VERSION ""

NS_ :

BS_:

BU_: INTERCEPTOR EBCM NEO ADAS PCM EPS VSA SCM BDY XXX EPB Vector__XXX EON S

BO_ 57 XXX_1: 3 XXX
 SG_ COUNTER : 21|2@0+ (1,0) [0|15] "" NEO
 SG_ CHECKSUM : 19|4@0+ (1,0) [0|3] "" NEO

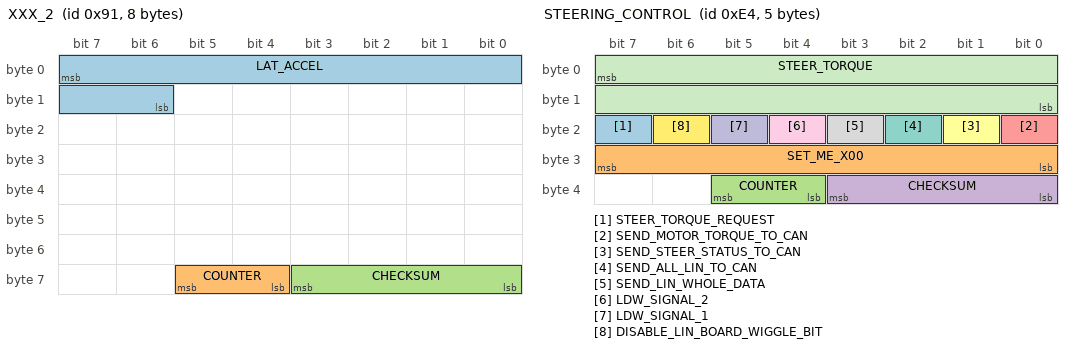
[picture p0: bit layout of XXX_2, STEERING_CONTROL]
BO_ 145 XXX_2: 8 XXX
 SG_ LAT_ACCEL : 7|10@0+ (0.02,-512) [-20|20] "m/s2" NEO
 SG_ COUNTER : 61|2@0+ (1,0) [0|3] "" NEO
 SG_ CHECKSUM : 59|4@0+ (1,0) [0|15] "" NEO

BO_ 228 STEERING_CONTROL: 5 ADAS
 SG_ STEER_TORQUE_REQUEST : 23|1@0+ (1,0) [0|1] "" EPS
 SG_ SET_ME_X00 : 31|8@0+ (1,0) [0|0] "" EPS
 SG_ COUNTER : 37|2@0+ (1,0) [0|3] "" EPS
 SG_ CHECKSUM : 35|4@0+ (1,0) [0|3] "" EPS
 SG_ SEND_MOTOR_TORQUE_TO_CAN : 16|1@0+ (1,0) [0|1] "" XXX
 SG_ SEND_STEER_STATUS_TO_CAN : 17|1@0+ (1,0) [0|1] "" XXX
 SG_ SEND_ALL_LIN_TO_CAN : 18|1@0+ (1,0) [0|1] "" XXX
 SG_ SEND_LIN_WHOLE_DATA : 19|1@0+ (1,0) [0|1] "" XXX
 SG_ LDW_SIGNAL_2 : 20|1@0+ (1,0) [0|1] "" XXX
 SG_ LDW_SIGNAL_1 : 21|1@0+ (1,0) [0|1] "" XXX
 SG_ STEER_TORQUE : 7|16@0- (1,0) [-3840|3840] "" EPS
 SG_ DISABLE_LIN_BOARD_WIGGLE_BIT : 22|1@0+ (1,0) [0|1] "" XXX

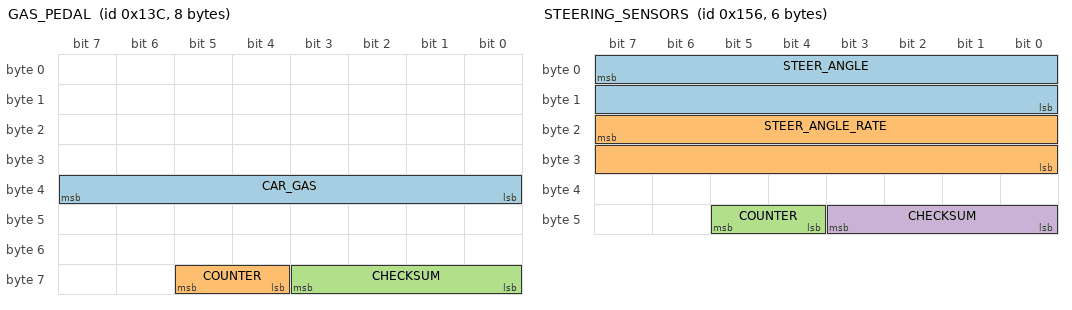
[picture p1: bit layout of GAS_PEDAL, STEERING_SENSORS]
BO_ 316 GAS_PEDAL: 8 PCM
 SG_ CAR_GAS : 39|8@0+ (1,0) [0|255] "" NEO
 SG_ COUNTER : 61|2@0+ (1,0) [0|3] "" NEO
 SG_ CHECKSUM : 59|4@0+ (1,0) [0|15] "" NEO

BO_ 342 STEERING_SENSORS: 6 EPS
 SG_ STEER_ANGLE : 7|16@0- (-0.1,0) [-500|500] "deg" NEO
 SG_ STEER_ANGLE_RATE : 23|16@0- (1,0) [-3000|3000] "deg/s" NEO
 SG_ COUNTER : 45|2@0+ (1,0) [0|3] "" NEO
 SG_ CHECKSUM : 43|4@0+ (1,0) [0|15] "" NEO

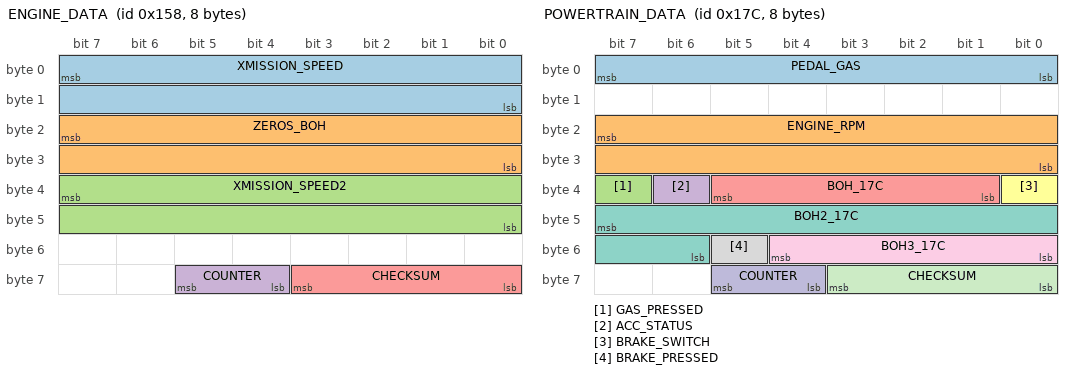
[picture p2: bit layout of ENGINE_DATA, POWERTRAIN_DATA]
BO_ 344 ENGINE_DATA: 8 PCM
 SG_ XMISSION_SPEED : 7|16@0+ (0.002759506,0) [0|70] "m/s" NEO
 SG_ ZEROS_BOH : 23|16@0+ (1,0) [0|15000] "" NEO
 SG_ XMISSION_SPEED2 : 39|16@0+ (0.002759506,0) [0|70] "m/s" NEO
 SG_ COUNTER : 61|2@0+ (1,0) [0|3] "" NEO
 SG_ CHECKSUM : 59|4@0+ (1,0) [0|15] "" NEO

BO_ 380 POWERTRAIN_DATA: 8 PCM
 SG_ PEDAL_GAS : 7|8@0+ (1,0) [0|255] "" NEO
 SG_ ENGINE_RPM : 23|16@0+ (1,0) [0|15000] "rpm" NEO
 SG_ GAS_PRESSED : 39|1@0+ (1,0) [0|1] "" NEO
 SG_ ACC_STATUS : 38|1@0+ (1,0) [0|1] "rpm" EON
 SG_ BOH_17C : 37|5@0+ (1,0) [0|1] "rpm" NEO
 SG_ BRAKE_SWITCH : 32|1@0+ (1,0) [0|1] "rpm" NEO
 SG_ BOH2_17C : 47|10@0+ (1,0) [0|1] "rpm" NEO
 SG_ BRAKE_PRESSED : 53|1@0+ (1,0) [0|1] "" NEO
 SG_ BOH3_17C : 52|5@0+ (1,0) [0|1] "rpm" NEO
 SG_ COUNTER : 61|2@0+ (1,0) [0|3] "" NEO
 SG_ CHECKSUM : 59|4@0+ (1,0) [0|3] "" NEO

BO_ 398 XXX_3: 3 XXX
 SG_ COUNTER : 21|2@0+ (1,0) [0|15] "" XXX
 SG_ CHECKSUM : 19|4@0+ (1,0) [0|3] "" XXX

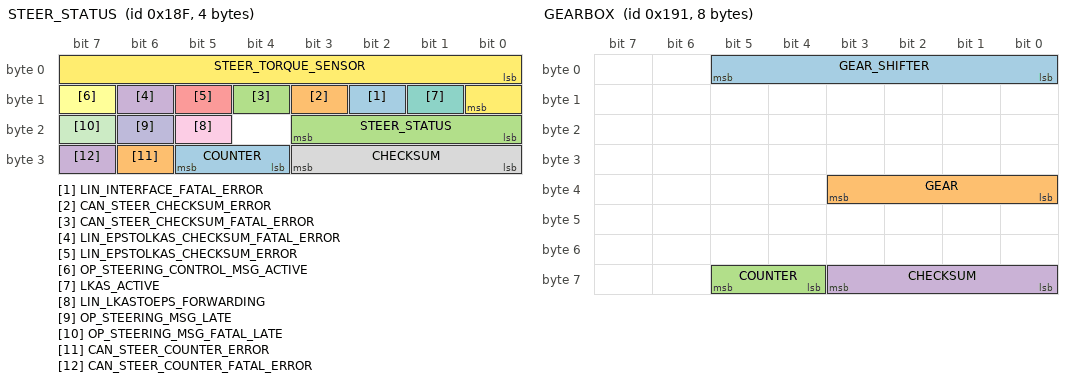
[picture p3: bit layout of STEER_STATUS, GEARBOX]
BO_ 399 STEER_STATUS: 4 EPS
 SG_ LIN_INTERFACE_FATAL_ERROR : 10|1@0+ (1,0) [0|1] "" XXX
 SG_ CAN_STEER_CHECKSUM_ERROR : 11|1@0+ (1,0) [0|1] "" XXX
 SG_ CAN_STEER_CHECKSUM_FATAL_ERROR : 12|1@0+ (1,0) [0|1] "" XXX
 SG_ LIN_EPSTOLKAS_CHECKSUM_FATAL_ERROR : 14|1@0+ (1,0) [0|1] "" XXX
 SG_ LIN_EPSTOLKAS_CHECKSUM_ERROR : 13|1@0+ (1,0) [0|1] "" XXX
 SG_ OP_STEERING_CONTROL_MSG_ACTIVE : 15|1@0+ (1,0) [0|1] "" XXX
 SG_ LKAS_ACTIVE : 9|1@0+ (1,0) [0|1] "" XXX
 SG_ CHECKSUM : 27|4@0+ (1,0) [0|3] "" EON
 SG_ LIN_LKASTOEPS_FORWARDING : 21|1@0+ (1,0) [0|1] "" XXX
 SG_ OP_STEERING_MSG_LATE : 22|1@0+ (1,0) [0|1] "" XXX
 SG_ OP_STEERING_MSG_FATAL_LATE : 23|1@0+ (1,0) [0|1] "" XXX
 SG_ STEER_TORQUE_SENSOR : 0|9@1- (1,0) [-256|256] "" XXX
 SG_ COUNTER : 29|2@0+ (1,0) [0|3] "" EON
 SG_ CAN_STEER_COUNTER_ERROR : 30|1@0+ (1,0) [0|1] "" XXX
 SG_ STEER_STATUS : 16|4@1+ (1,0) [0|15] "" XXX
 SG_ CAN_STEER_COUNTER_FATAL_ERROR : 31|1@0+ (1,0) [0|1] "" XXX

BO_ 401 GEARBOX: 8 PCM
 SG_ GEAR_SHIFTER : 5|6@0+ (1,0) [0|63] "" NEO
 SG_ GEAR : 35|4@0+ (1,0) [0|15] "" NEO
 SG_ COUNTER : 61|2@0+ (1,0) [0|3] "" NEO
 SG_ CHECKSUM : 59|4@0+ (1,0) [0|15] "" NEO

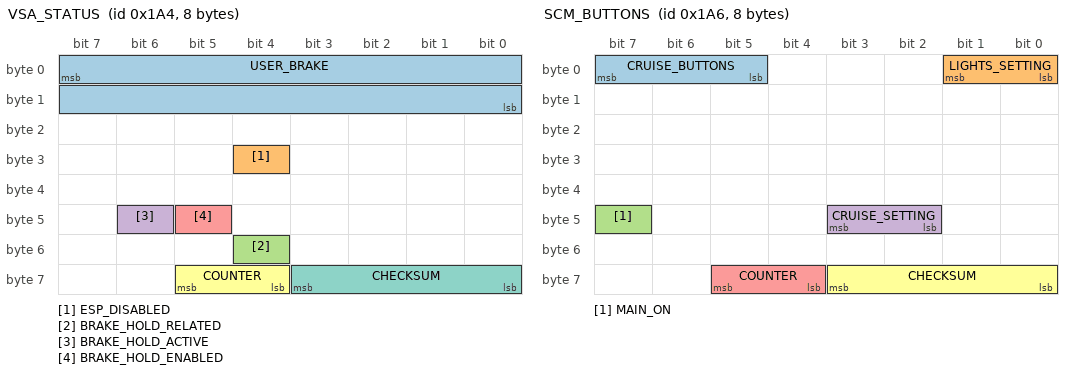
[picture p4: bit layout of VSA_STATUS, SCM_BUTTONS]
BO_ 420 VSA_STATUS: 8 VSA
 SG_ USER_BRAKE : 7|16@0+ (0.015625,-1.609375) [0|1000] "" EON
 SG_ ESP_DISABLED : 28|1@0+ (1,0) [0|1] "" EON
 SG_ BRAKE_HOLD_RELATED : 52|1@0+ (1,0) [0|1] "" XXX
 SG_ BRAKE_HOLD_ACTIVE : 46|1@0+ (1,0) [0|1] "" EON
 SG_ BRAKE_HOLD_ENABLED : 45|1@0+ (1,0) [0|1] "" EON
 SG_ COUNTER : 61|2@0+ (1,0) [0|3] "" EON
 SG_ CHECKSUM : 59|4@0+ (1,0) [0|15] "" EON

BO_ 422 SCM_BUTTONS: 8 SCM
 SG_ CRUISE_BUTTONS : 7|3@0+ (1,0) [0|7] "" NEO
 SG_ LIGHTS_SETTING : 1|2@0+ (1,0) [0|3] "" NEO
 SG_ MAIN_ON : 47|1@0+ (1,0) [0|1] "" NEO
 SG_ CRUISE_SETTING : 43|2@0+ (1,0) [0|3] "" NEO
 SG_ COUNTER : 61|2@0+ (1,0) [0|3] "" NEO
 SG_ CHECKSUM : 59|4@0+ (1,0) [0|15] "" NEO

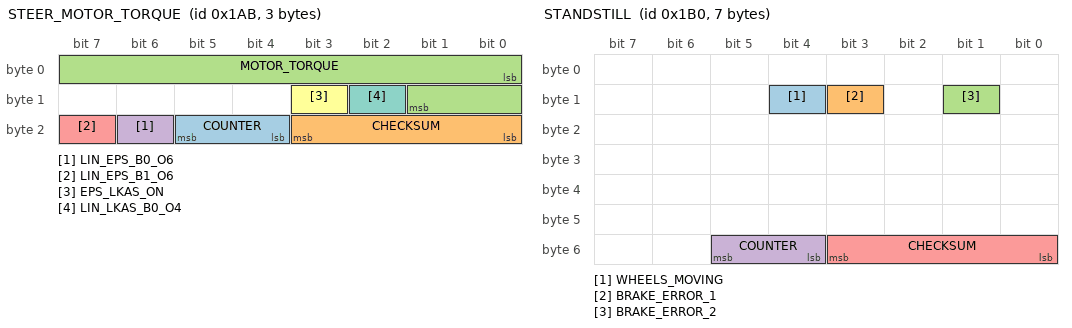
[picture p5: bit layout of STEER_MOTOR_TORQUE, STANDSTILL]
BO_ 427 STEER_MOTOR_TORQUE: 3 EPS
 SG_ COUNTER : 21|2@0+ (1,0) [0|3] "" EON
 SG_ CHECKSUM : 19|4@0+ (1,0) [0|15] "" EON
 SG_ MOTOR_TORQUE : 0|10@1- (1,0) [-512|512] "" XXX
 SG_ LIN_EPS_B0_O6 : 22|1@0+ (1,0) [0|1] "" XXX
 SG_ LIN_EPS_B1_O6 : 23|1@0+ (1,0) [0|1] "" XXX
 SG_ EPS_LKAS_ON : 11|1@0+ (1,0) [0|1] "" XXX
 SG_ LIN_LKAS_B0_O4 : 10|1@0+ (1,0) [0|1] "" XXX

BO_ 426 XXX_4: 8 VSA
 SG_ COUNTER : 61|2@0+ (1,0) [0|3] "" NEO
 SG_ CHECKSUM : 59|4@0+ (1,0) [0|15] "" NEO

BO_ 432 STANDSTILL: 7 VSA
 SG_ WHEELS_MOVING : 12|1@0+ (1,0) [0|1] "" NEO
 SG_ BRAKE_ERROR_1 : 11|1@0+ (1,0) [0|1] "" NEO
 SG_ BRAKE_ERROR_2 : 9|1@0+ (1,0) [0|1] "" NEO
 SG_ COUNTER : 53|2@0+ (1,0) [0|3] "" NEO
 SG_ CHECKSUM : 51|4@0+ (1,0) [0|15] "" NEO

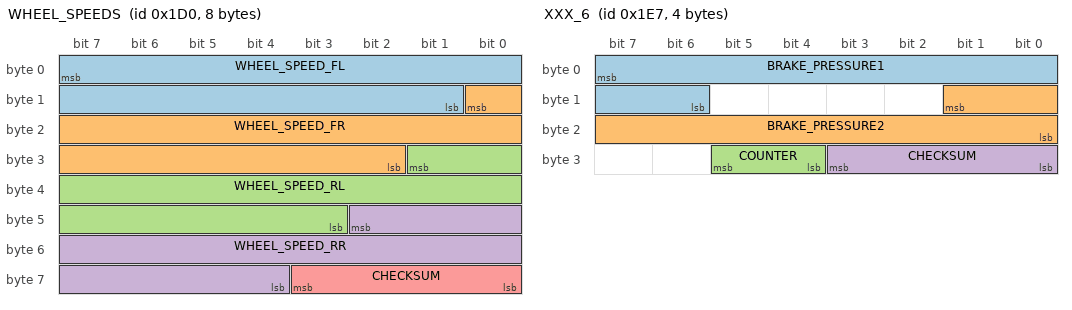
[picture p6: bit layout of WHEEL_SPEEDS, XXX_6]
BO_ 464 WHEEL_SPEEDS: 8 VSA
 SG_ WHEEL_SPEED_FL : 7|15@0+ (0.01,0) [0|250] "kph" EON
 SG_ WHEEL_SPEED_FR : 8|15@0+ (0.01,0) [0|250] "kph" EON
 SG_ WHEEL_SPEED_RL : 25|15@0+ (0.01,0) [0|250] "kph" EON
 SG_ WHEEL_SPEED_RR : 42|15@0+ (0.01,0) [0|250] "kph" EON
 SG_ CHECKSUM : 59|4@0+ (1,0) [0|3] "" EON

BO_ 476 XXX_5: 4 XXX
 SG_ COUNTER : 29|2@0+ (1,0) [0|3] "" XXX
 SG_ CHECKSUM : 27|4@0+ (1,0) [0|15] "" XXX

BO_ 487 XXX_6: 4 VSA
 SG_ BRAKE_PRESSURE1 : 7|10@0+ (0.015625,-103) [0|1000] "" NEO
 SG_ BRAKE_PRESSURE2 : 9|10@0+ (0.015625,-103) [0|1000] "" NEO
 SG_ COUNTER : 29|2@0+ (1,0) [0|3] "" XXX
 SG_ CHECKSUM : 27|4@0+ (1,0) [0|15] "" XXX

BO_ 490 VEHICLE_DYNAMICS: 8 VSA
 SG_ LONG_ACCEL : 23|16@0- (0.0015384,0) [-20|20] "m/s2" NEO
 SG_ COUNTER : 61|2@0+ (1,0) [0|3] "" XXX
 SG_ CHECKSUM : 59|4@0+ (1,0) [0|15] "" XXX

BO_ 506 BRAKE_COMMAND: 8 ADAS
 SG_ COMPUTER_BRAKE : 7|10@0+ (1,0) [0|1] "" EBCM
 SG_ SET_ME_X00 : 13|5@0+ (1,0) [0|1] "" EBCM
 SG_ BRAKE_PUMP_REQUEST : 8|1@0+ (1,0) [0|1] "" EBCM
 SG_ SET_ME_X00_2 : 23|3@0+ (1,0) [0|1] "" EBCM
 SG_ CRUISE_OVERRIDE : 20|1@0+ (1,0) [0|1] "" EBCM
 SG_ SET_ME_X00_3 : 19|1@0+ (1,0) [0|1] "" EBCM
 SG_ CRUISE_FAULT_CMD : 18|1@0+ (1,0) [0|1] "" EBCM
 SG_ CRUISE_CANCEL_CMD : 17|1@0+ (1,0) [0|1] "" EBCM
 SG_ COMPUTER_BRAKE_REQUEST : 16|1@0+ (1,0) [0|1] "" EBCM
 SG_ SET_ME_1 : 31|1@0+ (1,0) [0|1] "" EBCM
 SG_ AEB_REQ_1 : 29|1@0+ (1,0) [0|1] "" XXX
 SG_ AEB_REQ_2 : 26|3@0+ (1,0) [0|7] "" XXX
 SG_ BRAKE_LIGHTS : 39|1@0+ (1,0) [0|1] "" EBCM
 SG_ CRUISE_STATES : 38|7@0+ (1,0) [0|1] "" EBCM
 SG_ CHIME : 47|3@0+ (1,0) [0|7] "" EBCM
 SG_ SET_ME_X00_4 : 44|1@0+ (1,0) [0|1] "" EBCM
 SG_ FCW : 43|2@0+ (1,0) [0|3] "" EBCM
 SG_ AEB_STATUS : 41|2@0+ (1,0) [0|3] "" XXX
 SG_ SET_ME_X00_5 : 55|8@0+ (1,0) [0|0] "" EBCM
 SG_ COUNTER : 61|2@0+ (1,0) [0|3] "" EBCM
 SG_ CHECKSUM : 59|4@0+ (1,0) [0|15] "" EBCM

BO_ 507 XXX_7: 1 XXX

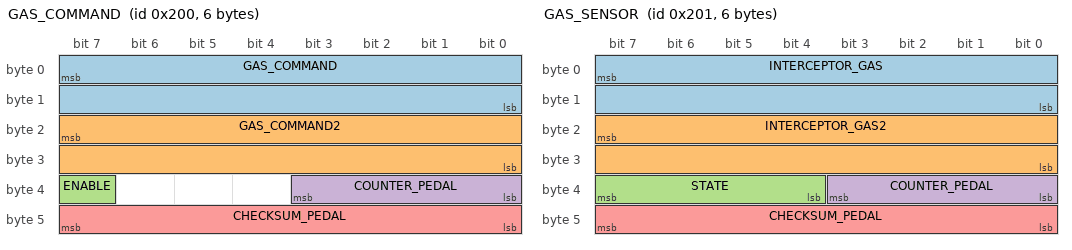
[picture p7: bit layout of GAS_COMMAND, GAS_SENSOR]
BO_ 512 GAS_COMMAND: 6 EON
 SG_ GAS_COMMAND : 7|16@0+ (0.126992032,-83.3) [0|1] "" INTERCEPTOR
 SG_ GAS_COMMAND2 : 23|16@0+ (0.253984064,-83.3) [0|1] "" INTERCEPTOR
 SG_ ENABLE : 39|1@0+ (1,0) [0|1] "" INTERCEPTOR
 SG_ COUNTER_PEDAL : 35|4@0+ (1,0) [0|15] "" INTERCEPTOR
 SG_ CHECKSUM_PEDAL : 47|8@0+ (1,0) [0|255] "" INTERCEPTOR

BO_ 513 GAS_SENSOR: 6 INTERCEPTOR
 SG_ INTERCEPTOR_GAS : 7|16@0+ (0.126992032,-83.3) [0|1] "" EON
 SG_ INTERCEPTOR_GAS2 : 23|16@0+ (0.253984064,-83.3) [0|1] "" EON
 SG_ STATE : 39|4@0+ (1,0) [0|15] "" EON
 SG_ COUNTER_PEDAL : 35|4@0+ (1,0) [0|15] "" EON
 SG_ CHECKSUM_PEDAL : 47|8@0+ (1,0) [0|255] "" EON

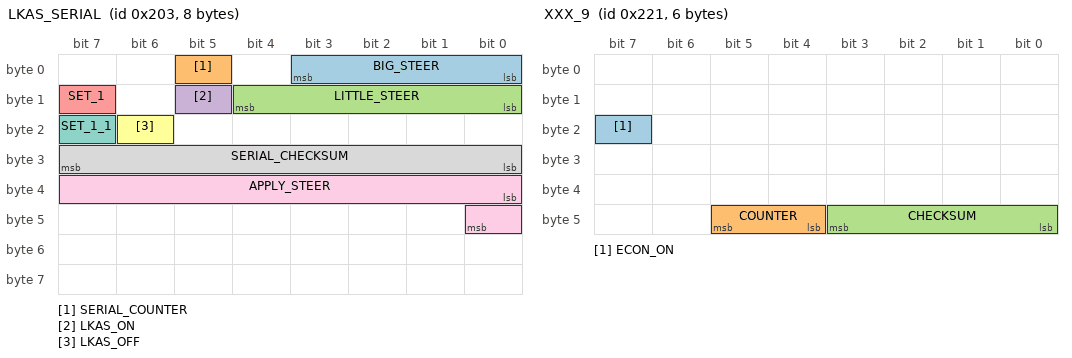
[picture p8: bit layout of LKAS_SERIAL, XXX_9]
BO_ 515 LKAS_SERIAL: 8 XXX
 SG_ BIG_STEER : 3|4@0- (1,0) [0|15] "" XXX
 SG_ SERIAL_COUNTER : 5|1@0+ (1,0) [0|1] "" XXX
 SG_ LITTLE_STEER : 12|5@0- (1,0) [0|31] "" XXX
 SG_ LKAS_ON : 13|1@0+ (1,0) [0|1] "" XXX
 SG_ SET_1 : 15|1@0+ (1,0) [0|1] "" XXX
 SG_ LKAS_OFF : 22|1@0+ (1,0) [0|1] "" XXX
 SG_ SET_1_1 : 23|1@0+ (1,0) [0|1] "" XXX
 SG_ SERIAL_CHECKSUM : 24|8@1+ (1,32) [0|255] "" XXX
 SG_ APPLY_STEER : 32|9@1- (1,0) [-256|255] "" XXX

BO_ 542 XXX_8: 7 XXX
 SG_ COUNTER : 53|2@0+ (1,0) [0|3] "" XXX
 SG_ CHECKSUM : 51|4@0+ (1,0) [0|15] "" XXX

BO_ 545 XXX_9: 6 SCM
 SG_ ECON_ON : 23|1@0+ (1,0) [0|1] "" XXX
 SG_ COUNTER : 45|2@0+ (1,0) [0|3] "" BDY
 SG_ CHECKSUM : 43|4@0+ (1,0) [0|15] "" BDY

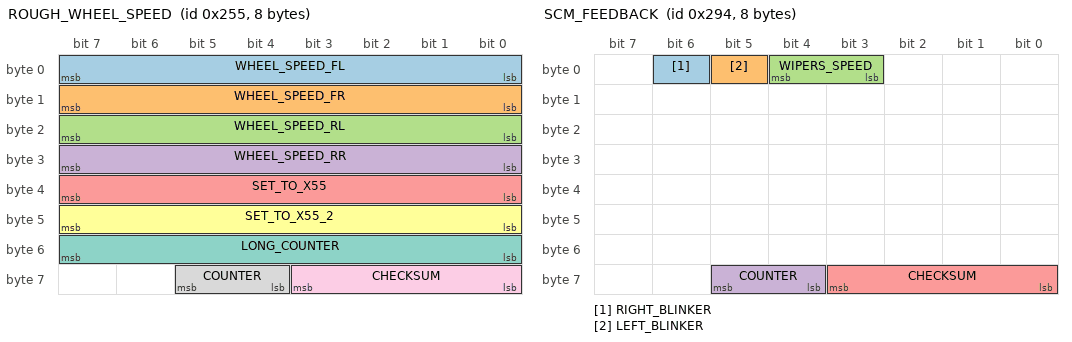
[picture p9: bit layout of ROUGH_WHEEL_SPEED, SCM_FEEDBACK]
BO_ 597 ROUGH_WHEEL_SPEED: 8 VSA
 SG_ WHEEL_SPEED_FL : 7|8@0+ (1,0) [0|255] "mph" NEO
 SG_ WHEEL_SPEED_FR : 15|8@0+ (1,0) [0|255] "mph" NEO
 SG_ WHEEL_SPEED_RL : 23|8@0+ (1,0) [0|255] "mph" NEO
 SG_ WHEEL_SPEED_RR : 31|8@0+ (1,0) [0|255] "mph" NEO
 SG_ SET_TO_X55 : 39|8@0+ (1,0) [0|255] "" XXX
 SG_ SET_TO_X55_2 : 47|8@0+ (1,0) [0|255] "" NEO
 SG_ LONG_COUNTER : 55|8@0+ (1,0) [0|255] "" XXX
 SG_ COUNTER : 61|2@0+ (1,0) [0|3] "" XXX
 SG_ CHECKSUM : 59|4@0+ (1,0) [0|15] "" XXX

BO_ 660 SCM_FEEDBACK: 8 SCM
 SG_ RIGHT_BLINKER : 6|1@0+ (1,0) [0|1] "" NEO
 SG_ LEFT_BLINKER : 5|1@0+ (1,0) [0|1] "" NEO
 SG_ WIPERS_SPEED : 4|2@0+ (1,0) [0|3] "" NEO
 SG_ COUNTER : 61|2@0+ (1,0) [0|3] "" XXX
 SG_ CHECKSUM : 59|4@0+ (1,0) [0|15] "" XXX

BO_ 661 XXX_10: 4 XXX
 SG_ COUNTER : 29|2@0+ (1,0) [0|3] "" XXX
 SG_ CHECKSUM : 27|4@0+ (1,0) [0|15] "" XXX

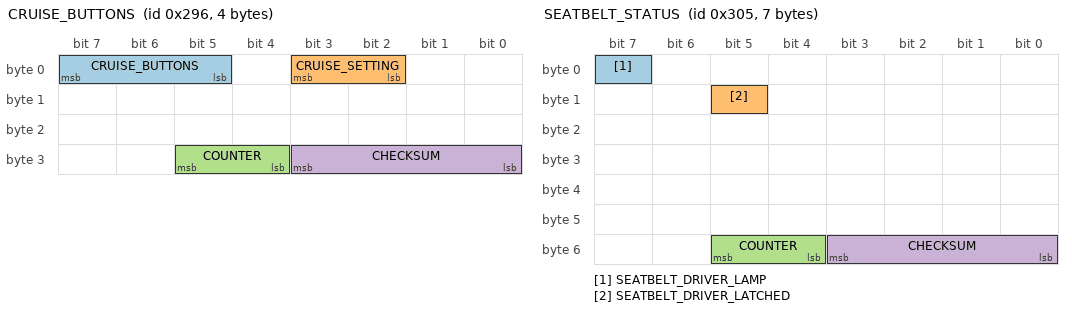
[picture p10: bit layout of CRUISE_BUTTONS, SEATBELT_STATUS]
BO_ 662 CRUISE_BUTTONS: 4 SCM
 SG_ CRUISE_BUTTONS : 7|3@0+ (1,0) [0|7] "" NEO
 SG_ CRUISE_SETTING : 3|2@0+ (1,0) [0|3] "" NEO
 SG_ COUNTER : 29|2@0+ (1,0) [0|3] "" XXX
 SG_ CHECKSUM : 27|4@0+ (1,0) [0|15] "" XXX

BO_ 773 SEATBELT_STATUS: 7 BDY
 SG_ SEATBELT_DRIVER_LAMP : 7|1@0+ (1,0) [0|1] "" NEO
 SG_ SEATBELT_DRIVER_LATCHED : 13|1@0+ (1,0) [0|1] "" NEO
 SG_ COUNTER : 53|2@0+ (1,0) [0|3] "" NEO
 SG_ CHECKSUM : 51|4@0+ (1,0) [0|15] "" NEO

BO_ 777 XXX_11: 8 XXX
 SG_ COUNTER : 61|2@0+ (1,0) [0|3] "" XXX
 SG_ CHECKSUM : 59|4@0+ (1,0) [0|15] "" XXX

BO_ 780 ACC_HUD: 8 ADAS
 SG_ PCM_SPEED : 7|16@0+ (0.01,0) [0|250] "kph" BDY
 SG_ PCM_GAS : 23|7@0+ (1,0) [0|127] "" BDY
 SG_ ZEROS_BOH : 16|1@0+ (1,0) [0|255] "" BDY
 SG_ CRUISE_SPEED : 31|8@0+ (1,0) [0|255] "" BDY
 SG_ DTC_MODE : 39|1@0+ (1,0) [0|1] "" BDY
 SG_ BOH : 38|1@0+ (1,0) [0|1] "" BDY
 SG_ ACC_PROBLEM : 37|1@0+ (1,0) [0|1] "" BDY
 SG_ FCM_OFF : 36|1@0+ (1,0) [0|1] "" BDY
 SG_ FCM_OFF_2 : 35|1@0+ (1,0) [0|1] "" BDY
 SG_ FCM_PROBLEM : 34|1@0+ (1,0) [0|1] "" BDY
 SG_ RADAR_OBSTRUCTED : 33|1@0+ (1,0) [0|1] "" BDY
 SG_ ENABLE_MINI_CAR : 32|1@0+ (1,0) [0|1] "" BDY
 SG_ HUD_DISTANCE : 47|2@0+ (1,0) [0|3] "" BDY
 SG_ HUD_DISTANCE_3 : 52|1@0+ (1,0) [0|1] "" BDY
 SG_ HUD_LEAD : 45|2@0+ (1,0) [0|3] "" BDY
 SG_ BOH_3 : 43|1@0+ (1,0) [0|3] "" BDY
 SG_ BOH_4 : 42|1@0+ (1,0) [0|3] "" BDY
 SG_ BOH_5 : 41|1@0+ (1,0) [0|3] "" BDY
 SG_ CRUISE_CONTROL_LABEL : 40|1@0+ (1,0) [0|3] "" BDY
 SG_ SET_ME_X01_2 : 55|1@0+ (1,0) [0|1] "" BDY
 SG_ CHIME : 51|3@0+ (1,0) [0|1] "" BDY
 SG_ IMPERIAL_UNIT : 54|1@0+ (1,0) [0|1] "" BDY
 SG_ SET_ME_X01 : 48|1@0+ (1,0) [0|1] "" BDY
 SG_ ICONS : 63|2@0+ (1,0) [0|1] "" BDY
 SG_ COUNTER : 61|2@0+ (1,0) [0|3] "" BDY
 SG_ CHECKSUM : 59|4@0+ (1,0) [0|15] "" BDY

BO_ 800 XXX_12: 8 XXX
 SG_ COUNTER : 61|2@0+ (1,0) [0|3] "" XXX
 SG_ CHECKSUM : 59|4@0+ (1,0) [0|15] "" XXX

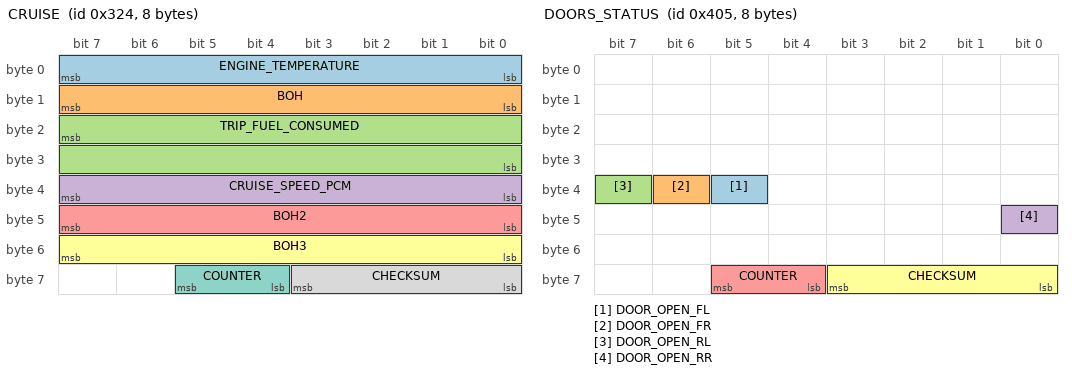
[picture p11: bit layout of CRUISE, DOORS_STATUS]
BO_ 804 CRUISE: 8 PCM
 SG_ ENGINE_TEMPERATURE : 7|8@0+ (1,0) [0|255] "" NEO
 SG_ BOH : 15|8@0+ (1,0) [0|255] "" NEO
 SG_ TRIP_FUEL_CONSUMED : 23|16@0+ (1,0) [0|255] "" NEO
 SG_ CRUISE_SPEED_PCM : 39|8@0+ (1,0) [0|255] "" NEO
 SG_ BOH2 : 47|8@0- (1,0) [0|255] "" NEO
 SG_ BOH3 : 55|8@0+ (1,0) [0|255] "" NEO
 SG_ COUNTER : 61|2@0+ (1,0) [0|3] "" NEO
 SG_ CHECKSUM : 59|4@0+ (1,0) [0|15] "" NEO

BO_ 808 XXX_13: 8 XXX
 SG_ COUNTER : 61|2@0+ (1,0) [0|3] "" XXX
 SG_ CHECKSUM : 59|4@0+ (1,0) [0|15] "" XXX

BO_ 829 LKAS_HUD: 5 ADAS
 SG_ CAM_TEMP_HIGH : 7|1@0+ (1,0) [0|255] "" BDY
 SG_ SET_ME_X41 : 6|7@0+ (1,0) [0|127] "" BDY
 SG_ BOH : 23|2@0+ (1,0) [0|4] "" BDY
 SG_ DASHED_LANES : 14|1@0+ (1,0) [0|1] "" BDY
 SG_ DTC : 13|1@0+ (1,0) [0|1] "" BDY
 SG_ LKAS_PROBLEM : 12|1@0+ (1,0) [0|1] "" BDY
 SG_ LKAS_OFF : 11|1@0+ (1,0) [0|1] "" BDY
 SG_ SOLID_LANES : 10|1@0+ (1,0) [0|1] "" BDY
 SG_ LDW_RIGHT : 9|1@0+ (1,0) [0|1] "" BDY
 SG_ STEERING_REQUIRED : 8|1@0+ (1,0) [0|1] "" BDY
 SG_ LDW_PROBLEM : 21|1@0+ (1,0) [0|1] "" BDY
 SG_ BEEP : 17|2@0+ (1,0) [0|1] "" BDY
 SG_ LDW_ON : 28|1@0+ (1,0) [0|1] "" BDY
 SG_ LDW_OFF : 27|1@0+ (1,0) [0|1] "" BDY
 SG_ CLEAN_WINDSHIELD : 26|1@0+ (1,0) [0|1] "" BDY
 SG_ SET_ME_X48 : 31|8@0+ (1,0) [0|255] "" BDY
 SG_ COUNTER : 37|2@0+ (1,0) [0|3] "" BDY
 SG_ CHECKSUM : 35|4@0+ (1,0) [0|15] "" BDY

BO_ 871 XXX_14: 8 XXX
 SG_ COUNTER : 61|2@0+ (1,0) [0|3] "" XXX
 SG_ CHECKSUM : 59|4@0+ (1,0) [0|15] "" XXX

BO_ 882 XXX_15: 2 XXX
 SG_ COUNTER : 13|2@0+ (1,0) [0|3] "" XXX
 SG_ CHECKSUM : 11|4@0+ (1,0) [0|15] "" XXX

BO_ 884 XXX_16: 8 XXX
 SG_ COUNTER : 61|2@0+ (1,0) [0|3] "" XXX
 SG_ CHECKSUM : 59|4@0+ (1,0) [0|15] "" XXX

BO_ 891 XXX_17: 8 XXX
 SG_ COUNTER : 61|2@0+ (1,0) [0|3] "" XXX
 SG_ CHECKSUM : 59|4@0+ (1,0) [0|15] "" XXX

BO_ 892 CRUISE_PARAMS: 8 PCM
 SG_ CRUISE_SPEED_OFFSET : 31|8@0- (0.1,0) [-128|127] "kph" NEO
 SG_ COUNTER : 61|2@0+ (1,0) [0|3] "" XXX
 SG_ CHECKSUM : 59|4@0+ (1,0) [0|15] "" XXX

BO_ 918 XXX_18: 7 XXX
 SG_ COUNTER : 53|2@0+ (1,0) [0|3] "" XXX
 SG_ CHECKSUM : 51|4@0+ (1,0) [0|15] "" XXX

BO_ 923 XXX_19: 2 XXX
 SG_ COUNTER : 13|2@0+ (1,0) [0|3] "" XXX
 SG_ CHECKSUM : 11|4@0+ (1,0) [0|15] "" XXX

BO_ 927 ACC_HUD_2: 8 ADAS
 SG_ ZEROS_BOH : 7|17@0+ (1,0) [0|127] "" BDY
 SG_ APPLY_BRAKES_FOR_CANC : 23|1@0+ (1,0) [0|15] "" BDY
 SG_ ZEROS_BOH2 : 31|8@0+ (1,0) [0|127] "" BDY
 SG_ RESUME_INSTRUCTION : 21|1@0+ (1,0) [0|15] "" BDY
 SG_ ACC_ALERTS : 20|5@0+ (1,0) [0|15] "" BDY
 SG_ LEAD_SPEED : 39|9@0+ (1,0) [0|127] "" BDY
 SG_ LEAD_STATE : 46|3@0+ (1,0) [0|127] "" BDY
 SG_ LEAD_DISTANCE : 43|5@0+ (1,0) [0|31] "" BDY
 SG_ ZEROS_BOH3 : 54|7@0+ (1,0) [0|127] "" BDY
 SG_ COUNTER : 61|2@0+ (1,0) [0|3] "" XXX
 SG_ CHECKSUM : 59|4@0+ (1,0) [0|15] "" XXX

BO_ 929 XXX_20: 8 XXX
 SG_ COUNTER : 61|2@0+ (1,0) [0|3] "" XXX
 SG_ CHECKSUM : 59|4@0+ (1,0) [0|15] "" XXX

BO_ 983 XXX_21: 8 XXX
 SG_ COUNTER : 61|2@0+ (1,0) [0|3] "" XXX
 SG_ CHECKSUM : 59|4@0+ (1,0) [0|15] "" XXX

BO_ 985 XXX_22: 3 XXX
 SG_ COUNTER : 21|2@0+ (1,0) [0|15] "" XXX
 SG_ CHECKSUM : 19|4@0+ (1,0) [0|3] "" XXX

BO_ 1024 RADAR_DIAGNOSTIC: 8 RADAR
 SG_ RADAR_STATE : 7|8@0+ (1,0) [0|255] "" NEO
 SG_ COUNTER : 37|2@0+ (1,0) [0|3] "" XXX
 SG_ CHECKSUM : 35|4@0+ (1,0) [0|15] "" XXX

BO_ 1027 XXX_24: 5 XXX
 SG_ COUNTER : 37|2@0+ (1,0) [0|3] "" XXX
 SG_ CHECKSUM : 35|4@0+ (1,0) [0|15] "" XXX

BO_ 1029 DOORS_STATUS: 8 BDY
 SG_ DOOR_OPEN_FL : 37|1@0+ (1,0) [0|1] "" NEO
 SG_ DOOR_OPEN_FR : 38|1@0+ (1,0) [0|1] "" NEO
 SG_ DOOR_OPEN_RL : 39|1@0+ (1,0) [0|1] "" NEO
 SG_ DOOR_OPEN_RR : 40|1@0+ (1,0) [0|1] "" NEO
 SG_ COUNTER : 61|2@0+ (1,0) [0|3] "" NEO
 SG_ CHECKSUM : 59|4@0+ (1,0) [0|15] "" NEO

BO_ 1036 XXX_25: 8 XXX
 SG_ COUNTER : 61|2@0+ (1,0) [0|3] "" XXX
 SG_ CHECKSUM : 59|4@0+ (1,0) [0|15] "" XXX

BO_ 1039 XXX_26: 8 XXX
 SG_ COUNTER : 61|2@0+ (1,0) [0|3] "" XXX
 SG_ CHECKSUM : 59|4@0+ (1,0) [0|15] "" XXX

BO_ 1057 XXX_110: 8 RADAR
 SG_ COUNTER : 61|2@0+ (1,0) [0|3] "" XXX
 SG_ CHECKSUM : 59|4@0+ (1,0) [0|15] "" XXX

BO_ 1064 XXX_28: 7 XXX
 SG_ COUNTER : 53|2@0+ (1,0) [0|3] "" XXX
 SG_ CHECKSUM : 51|4@0+ (1,0) [0|15] "" XXX

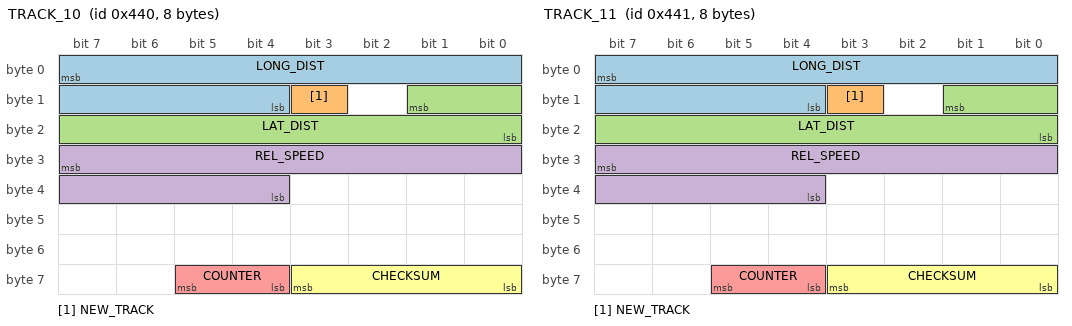
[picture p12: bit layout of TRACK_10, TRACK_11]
BO_ 1088 TRACK_10: 8 RADAR
 SG_ LONG_DIST : 7|12@0+ (0.0625,0) [0|255.5] "m" NEO
 SG_ NEW_TRACK : 11|1@0+ (1,0) [0|1] "" NEO
 SG_ LAT_DIST : 9|10@0- (0.0625,0) [0|63.5] "m" NEO
 SG_ REL_SPEED : 31|12@0- (0.03125,0) [0|127.5] "m/s" NEO
 SG_ COUNTER : 61|2@0+ (1,0) [0|3] "" XXX
 SG_ CHECKSUM : 59|4@0+ (1,0) [0|15] "" XXX

BO_ 1089 TRACK_11: 8 RADAR
 SG_ LONG_DIST : 7|12@0+ (0.0625,0) [0|255.5] "m" NEO
 SG_ NEW_TRACK : 11|1@0+ (1,0) [0|1] "" NEO
 SG_ LAT_DIST : 9|10@0- (0.0625,0) [0|63.5] "m" NEO
 SG_ REL_SPEED : 31|12@0- (0.03125,0) [0|127.5] "m/s" NEO
 SG_ COUNTER : 61|2@0+ (1,0) [0|3] "" XXX
 SG_ CHECKSUM : 59|4@0+ (1,0) [0|15] "" XXX

BO_ 1108 XXX_31: 8 XXX
 SG_ COUNTER : 61|2@0+ (1,0) [0|3] "" XXX
 SG_ CHECKSUM : 59|4@0+ (1,0) [0|15] "" XXX

BO_ 1125 XXX_32: 8 XXX
 SG_ COUNTER : 61|2@0+ (1,0) [0|3] "" XXX
 SG_ CHECKSUM : 59|4@0+ (1,0) [0|15] "" XXX

BO_ 1296 XXX_33: 3 XXX
 SG_ COUNTER : 21|2@0+ (1,0) [0|15] "" XXX
 SG_ CHECKSUM : 19|4@0+ (1,0) [0|3] "" XXX

BO_ 1365 XXX_34: 5 XXX
 SG_ COUNTER : 37|2@0+ (1,0) [0|3] "" XXX
 SG_ CHECKSUM : 35|4@0+ (1,0) [0|15] "" XXX

BO_ 1424 XXX_35: 5 XXX
 SG_ COUNTER : 37|2@0+ (1,0) [0|3] "" XXX
 SG_ CHECKSUM : 35|4@0+ (1,0) [0|15] "" XXX

BO_ 1600 XXX_36: 5 XXX
 SG_ COUNTER : 37|2@0+ (1,0) [0|3] "" XXX
 SG_ CHECKSUM : 35|4@0+ (1,0) [0|15] "" XXX

BO_ 1601 XXX_37: 8 XXX
 SG_ COUNTER : 61|2@0+ (1,0) [0|3] "" XXX
 SG_ CHECKSUM : 59|4@0+ (1,0) [0|15] "" XXX

BO_ 1633 XXX_38: 8 XXX
 SG_ COUNTER : 61|2@0+ (1,0) [0|3] "" XXX
 SG_ CHECKSUM : 59|4@0+ (1,0) [0|15] "" XXX

BO_ 768 VEHICLE_STATE: 8 ADAS
 SG_ SET_ME_XF9 : 7|8@0+ (1,0) [0|255] "" Vector__XXX
 SG_ VEHICLE_SPEED : 15|8@0+ (1,0) [0|255] "kph" Vector__XXX

BO_ 769 VEHICLE_STATE2: 8 ADAS
 SG_ SET_ME_0F18510 : 7|28@0+ (1,0) [0|268435455] "" Vector__XXX
 SG_ SET_ME_25A0000 : 27|28@0+ (1,0) [0|268435455] "" Vector__XXX

BO_ 1040 XXX_101: 8 RADAR

BO_ 1041 XXX_102: 8 RADAR

BO_ 1042 XXX_103: 8 RADAR

BO_ 1043 XXX_104: 8 RADAR
 SG_ NEW_SIGNAL_1 : 55|1@0+ (1,0) [0|1] "" XXX

BO_ 1044 XXX_105: 8 RADAR
 SG_ NEW_SIGNAL_1 : 59|1@0+ (1,0) [0|1] "" XXX

BO_ 1045 XXX_106: 8 RADAR

BO_ 1046 XXX_107: 8 RADAR

BO_ 1047 XXX_108: 8 RADAR

BO_ 1056 XXX_109: 8 RADAR

BO_ 1058 XXX_111: 8 RADAR

BO_ 1059 XXX_112: 8 RADAR

BO_ 1060 XXX_113: 8 RADAR

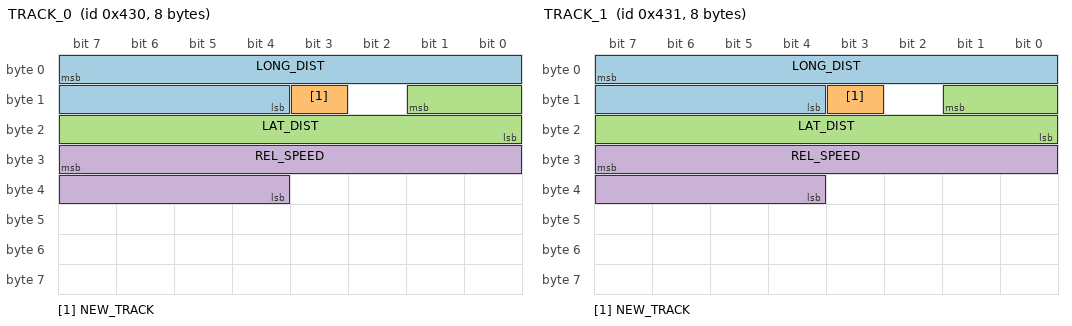
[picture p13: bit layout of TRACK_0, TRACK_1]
BO_ 1072 TRACK_0: 8 RADAR
 SG_ LONG_DIST : 7|12@0+ (0.0625,0) [0|255.5] "m" NEO
 SG_ NEW_TRACK : 11|1@0+ (1,0) [0|1] "" NEO
 SG_ LAT_DIST : 9|10@0- (0.0625,0) [0|63.5] "m" NEO
 SG_ REL_SPEED : 31|12@0- (0.03125,0) [0|127.5] "m/s" NEO

BO_ 1073 TRACK_1: 8 RADAR
 SG_ LONG_DIST : 7|12@0+ (0.0625,0) [0|255.5] "m" NEO
 SG_ NEW_TRACK : 11|1@0+ (1,0) [0|1] "" NEO
 SG_ LAT_DIST : 9|10@0- (0.0625,0) [0|63.5] "m" NEO
 SG_ REL_SPEED : 31|12@0- (0.03125,0) [0|127.5] "m/s" NEO

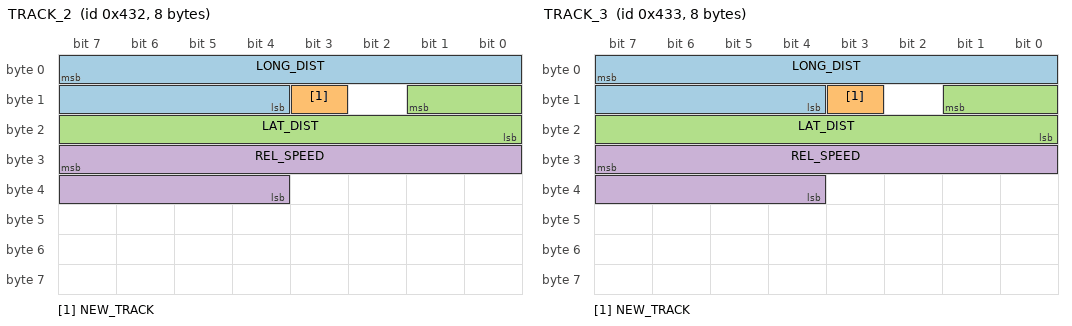
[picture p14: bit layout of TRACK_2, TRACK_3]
BO_ 1074 TRACK_2: 8 RADAR
 SG_ LONG_DIST : 7|12@0+ (0.0625,0) [0|255.5] "m" NEO
 SG_ NEW_TRACK : 11|1@0+ (1,0) [0|1] "" NEO
 SG_ LAT_DIST : 9|10@0- (0.0625,0) [0|63.5] "m" NEO
 SG_ REL_SPEED : 31|12@0- (0.03125,0) [0|127.5] "m/s" NEO

BO_ 1075 TRACK_3: 8 RADAR
 SG_ LONG_DIST : 7|12@0+ (0.0625,0) [0|255.5] "m" NEO
 SG_ NEW_TRACK : 11|1@0+ (1,0) [0|1] "" NEO
 SG_ LAT_DIST : 9|10@0- (0.0625,0) [0|63.5] "m" NEO
 SG_ REL_SPEED : 31|12@0- (0.03125,0) [0|127.5] "m/s" NEO

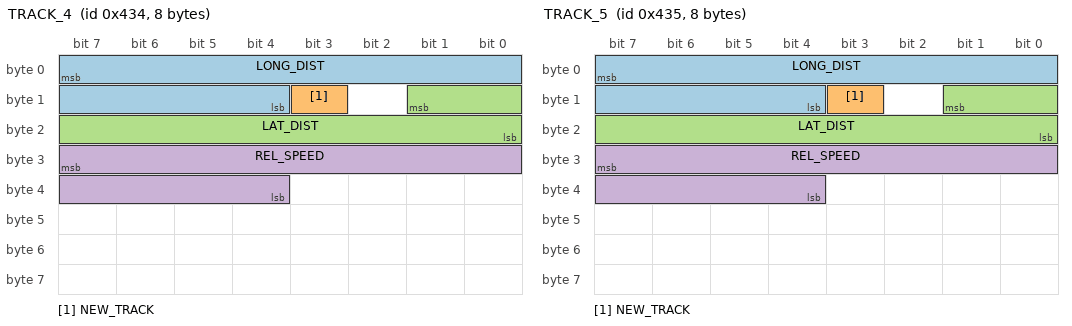
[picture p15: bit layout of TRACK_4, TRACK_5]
BO_ 1076 TRACK_4: 8 RADAR
 SG_ LONG_DIST : 7|12@0+ (0.0625,0) [0|255.5] "m" NEO
 SG_ NEW_TRACK : 11|1@0+ (1,0) [0|1] "" NEO
 SG_ LAT_DIST : 9|10@0- (0.0625,0) [0|63.5] "m" NEO
 SG_ REL_SPEED : 31|12@0- (0.03125,0) [0|127.5] "m/s" NEO

BO_ 1077 TRACK_5: 8 RADAR
 SG_ LONG_DIST : 7|12@0+ (0.0625,0) [0|255.5] "m" NEO
 SG_ NEW_TRACK : 11|1@0+ (1,0) [0|1] "" NEO
 SG_ LAT_DIST : 9|10@0- (0.0625,0) [0|63.5] "m" NEO
 SG_ REL_SPEED : 31|12@0- (0.03125,0) [0|127.5] "m/s" NEO

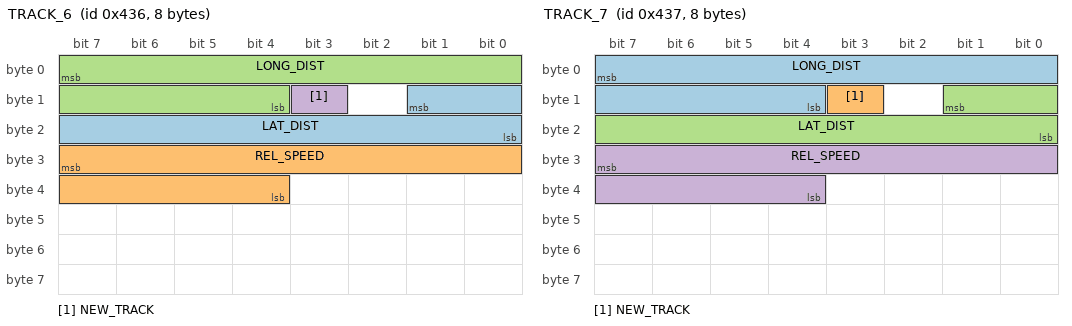
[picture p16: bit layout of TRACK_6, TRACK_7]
BO_ 1078 TRACK_6: 8 RADAR
 SG_ LAT_DIST : 9|10@0- (0.0625,0) [0|63.5] "m" NEO
 SG_ REL_SPEED : 31|12@0- (0.03125,0) [0|127.5] "m/s" NEO
 SG_ LONG_DIST : 7|12@0+ (0.0625,0) [0|255.5] "m" NEO
 SG_ NEW_TRACK : 11|1@0+ (1,0) [0|1] "" NEO

BO_ 1079 TRACK_7: 8 RADAR
 SG_ LONG_DIST : 7|12@0+ (0.0625,0) [0|255.5] "m" NEO
 SG_ NEW_TRACK : 11|1@0+ (1,0) [0|1] "" NEO
 SG_ LAT_DIST : 9|10@0- (0.0625,0) [0|63.5] "m" NEO
 SG_ REL_SPEED : 31|12@0- (0.03125,0) [0|127.5] "m/s" NEO

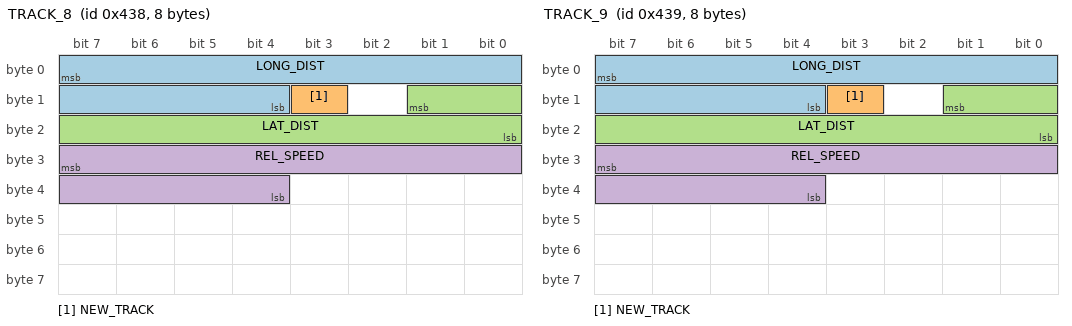
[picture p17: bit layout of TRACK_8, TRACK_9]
BO_ 1080 TRACK_8: 8 RADAR
 SG_ LONG_DIST : 7|12@0+ (0.0625,0) [0|255.5] "m" NEO
 SG_ NEW_TRACK : 11|1@0+ (1,0) [0|1] "" NEO
 SG_ LAT_DIST : 9|10@0- (0.0625,0) [0|63.5] "m" NEO
 SG_ REL_SPEED : 31|12@0- (0.03125,0) [0|127.5] "m/s" NEO

BO_ 1081 TRACK_9: 8 RADAR
 SG_ LONG_DIST : 7|12@0+ (0.0625,0) [0|255.5] "m" NEO
 SG_ NEW_TRACK : 11|1@0+ (1,0) [0|1] "" NEO
 SG_ LAT_DIST : 9|10@0- (0.0625,0) [0|63.5] "m" NEO
 SG_ REL_SPEED : 31|12@0- (0.03125,0) [0|127.5] "m/s" NEO

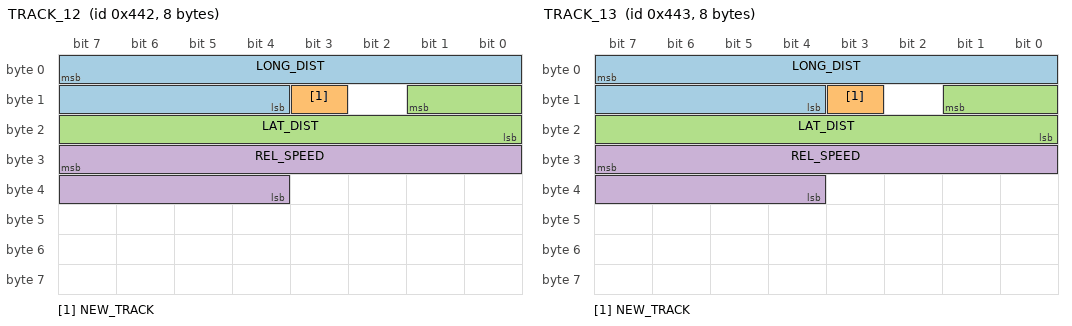
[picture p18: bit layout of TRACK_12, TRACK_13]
BO_ 1090 TRACK_12: 8 RADAR
 SG_ LONG_DIST : 7|12@0+ (0.0625,0) [0|255.5] "m" NEO
 SG_ NEW_TRACK : 11|1@0+ (1,0) [0|1] "" NEO
 SG_ LAT_DIST : 9|10@0- (0.0625,0) [0|63.5] "m" NEO
 SG_ REL_SPEED : 31|12@0- (0.03125,0) [0|127.5] "m/s" NEO

BO_ 1091 TRACK_13: 8 RADAR
 SG_ LONG_DIST : 7|12@0+ (0.0625,0) [0|255.5] "m" NEO
 SG_ NEW_TRACK : 11|1@0+ (1,0) [0|1] "" NEO
 SG_ LAT_DIST : 9|10@0- (0.0625,0) [0|63.5] "m" NEO
 SG_ REL_SPEED : 31|12@0- (0.03125,0) [0|127.5] "m/s" NEO

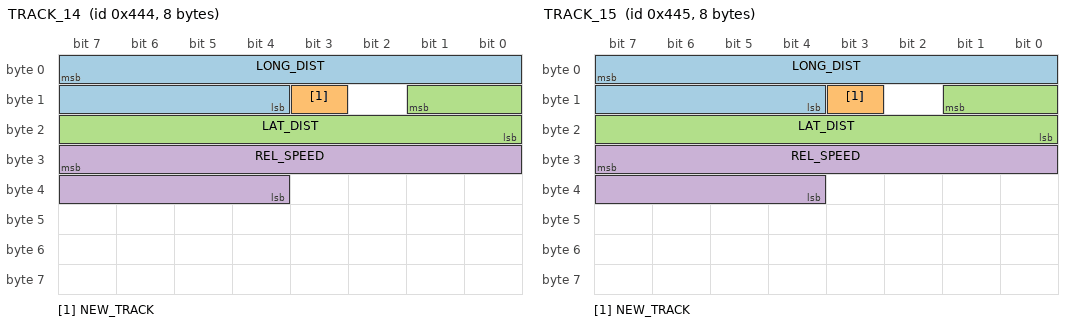
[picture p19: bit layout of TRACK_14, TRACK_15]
BO_ 1092 TRACK_14: 8 RADAR
 SG_ LONG_DIST : 7|12@0+ (0.0625,0) [0|255.5] "m" NEO
 SG_ NEW_TRACK : 11|1@0+ (1,0) [0|1] "" NEO
 SG_ LAT_DIST : 9|10@0- (0.0625,0) [0|63.5] "m" NEO
 SG_ REL_SPEED : 31|12@0- (0.03125,0) [0|127.5] "m/s" NEO

BO_ 1093 TRACK_15: 8 RADAR
 SG_ LONG_DIST : 7|12@0+ (0.0625,0) [0|255.5] "m" NEO
 SG_ NEW_TRACK : 11|1@0+ (1,0) [0|1] "" NEO
 SG_ LAT_DIST : 9|10@0- (0.0625,0) [0|63.5] "m" NEO
 SG_ REL_SPEED : 31|12@0- (0.03125,0) [0|127.5] "m/s" NEO

BO_ 521 LIN_DATA_IN: 8 XXX
 SG_ LITTLE_STEER : 12|5@0+ (1,0) [0|31] "" XXX
 SG_ LKAS_ENABLED_INVERT : 22|1@0+ (1,0) [0|1] "" XXX
 SG_ BIG_DRIVER_TORQUE : 24|4@1+ (1,0) [0|15] "" XXX
 SG_ SMALL_DRIVER_TORQUE : 36|5@0+ (1,0) [0|31] "" XXX
 SG_ SMALL_MOTOR_TORQUE : 54|7@0+ (1,0) [0|127] "" XXX
 SG_ BIG_STEER : 0|4@1+ (1,0) [0|15] "" XXX
 SG_ LKAS_ON_FROM_EPS : 37|1@0+ (1,0) [0|1] "" XXX
 SG_ CAN_CHECKSUM : 56|4@1+ (1,0) [0|15] "" XXX
 SG_ CAN_COUNTER : 61|2@0+ (1,0) [0|3] "" XXX
 SG_ EPS_TO_LKAS_COUNTER_BIT : 29|1@0+ (1,0) [0|1] "" XXX
 SG_ BIG_MOTOR_TORQUE : 45|3@0- (1,0) [0|7] "" XXX
 SG_ UNK_SIGNAL : 4|1@0+ (1,0) [0|1] "" XXX
 SG_ LKAS_ON_FROM_EPS_INVERT : 46|1@0+ (1,0) [0|1] "" XXX
 SG_ LIN_EPS_B1_O6 : 38|1@0+ (1,0) [0|1] "" XXX
 SG_ LIN_EPS_B0_O4 : 28|1@0+ (1,0) [0|1] "" XXX
 SG_ LIN_EPS_B2_O0_2 : 40|3@1+ (1,0) [0|7] "" XXX
 SG_ UNK_LDW_SIGNAL2 : 20|1@0+ (1,0) [0|1] "" XXX
 SG_ LKAS_ENABLED : 13|1@0+ (1,0) [0|1] "" XXX
 SG_ UNK_LDW_SIGNAL1 : 21|1@0+ (1,0) [0|1] "" XXX

BO_TX_BU_ 506 : NEO,ADAS;
BO_TX_BU_ 780 : NEO,ADAS;
BO_TX_BU_ 829 : NEO,ADAS;
BO_TX_BU_ 927 : NEO,ADAS;

CM_ SG_ 228 SEND_LIN_WHOLE_DATA "takes the MCU LKAS STEER_TORQUE, EPS ";
CM_ SG_ 228 LDW_SIGNAL_2 "LKAS B1O4";
CM_ SG_ 228 LDW_SIGNAL_1 "LKAS B1 5";
CM_ SG_ 228 DISABLE_LIN_BOARD_WIGGLE_BIT "this makes the apply_steer value never be the same. it will c hange the LSB. so it could actually go over OP max torque by 1.. this needs to be redone, but it works for now";
CM_ SG_ 399 OP_STEERING_CONTROL_MSG_ACTIVE "this comes on when the LIN_interface sees the 0xe4 message";
CM_ SG_ 399 STEER_STATUS "11 is EPS fail for oversteer. look at code for more";
CM_ SG_ 427 EPS_LKAS_ON "Signal from EPStoLKAS B1 O5";
CM_ SG_ 427 LIN_LKAS_B0_O4 "i think this signal says MCU would disengage given current factors...";
CM_ SG_ 515 APPLY_STEER "thi sis big_steer and little_steer put together";
CM_ SG_ 521 UNK_SIGNAL "ive never seen this move like this..";
VAL_ 401 GEAR_SHIFTER 32 "L" 16 "S" 8 "D" 4 "N" 2 "R" 1 "P" ;
VAL_ 513 STATE 5 "FAULT_TIMEOUT" 4 "FAULT_STARTUP" 3 "FAULT_SCE" 2 "FAULT_SEND" 1 "FAULT_BAD_CHECKSUM" 0 "NO_FAULT" ;
CM_ "CHFFR_METRIC 342 STEER_ANGLE STEER_ANGLE 0.36 180; CHFFR_METRIC 380 ENGINE_RPM ENGINE_RPM 1 0; CHFFR_METRIC 804 ENGINE_TEMPERATURE ENGINE_TEMPERATURE 1 0";
